VERSION ""

NS_ :

BS_:
BU_: MX5_ND2_2019
BO_ 576 Steering: 8 MX5_ND2_2019
   SG_ 0_SteeringTorque : 7|16@0+ (1,-32512) [0|1] "" MX5_ND2_2019

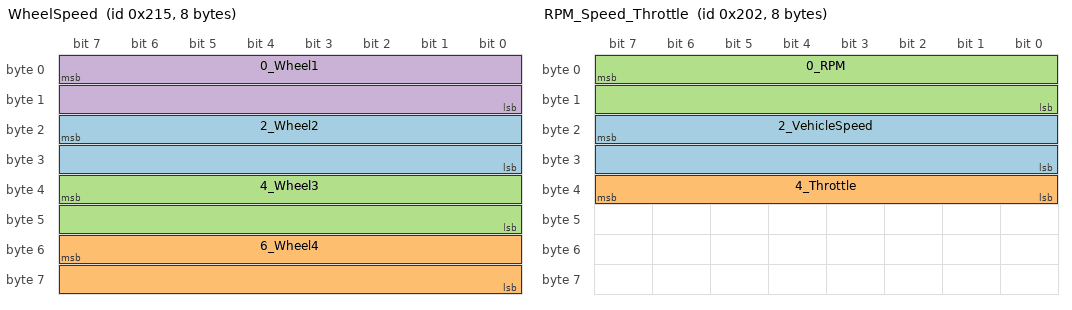
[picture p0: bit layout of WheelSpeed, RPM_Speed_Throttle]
BO_ 533 WheelSpeed: 8 MX5_ND2_2019
   SG_ 2_Wheel2 : 23|16@0+ (0.01,-100) [0|0] "" MX5_ND2_2019
   SG_ 6_Wheel4 : 55|16@0+ (0.01,-100) [0|0] "" MX5_ND2_2019
   SG_ 4_Wheel3 : 39|16@0+ (0.01,-100) [0|0] "" MX5_ND2_2019
   SG_ 0_Wheel1 : 7|16@0+ (0.01,-100) [0|0] "" MX5_ND2_2019

BO_ 357 Clutch_Gear_-_not_checked_yet: 8 MX5_ND2_2019
   SG_ 2_Clutch_Neutral : 23|8@0+ (1,0) [0|0] "" MX5_ND2_2019
   SG_ 6_CurrentGear : 55|8@0+ (1,0) [0|0] "" MX5_ND2_2019

BO_ 514 RPM_Speed_Throttle: 8 MX5_ND2_2019
   SG_ 2_VehicleSpeed : 23|16@0+ (0.01,0) [0|0] "kmh" Vector__XXX
   SG_ 4_Throttle : 39|8@0+ (0.4,0) [0|1] "percent" MX5_ND2_2019
   SG_ 0_RPM : 7|16@0+ (0.25,0) [0|0] "rpm" MX5_ND2_2019

BO_ 120 Brake: 8 MX5_ND2_2019
   SG_ BrakePressure : 39|16@0- (0.00152588,40) [0|100] "%" Vector__XXX

BO_ 2147484704 Temps: 8 MX5_ND2_2019
   SG_ 0_CoolantTemp : 7|8@0+ (1,-40) [0|1] "C" Vector__XXX

BO_ 2147484922 IAT: 8 MX5_ND2_2019
   SG_ 4_IntakeAirTemp : 39|8@0+ (1,-40) [0|1] "C" Vector__XXX

BO_ 2147483782 SteeringAngle: 8 MX5_ND2_2019
   SG_ 0_SteeringAngle : 7|16@0+ (-0.0228,365) [0|1] "" Vector__XXX

CM_ SG_ 357 6_CurrentGear "what_is_6th?";
BA_DEF_ BO_ "GenMsgBackgroundColor" STRING ;
BA_DEF_ BO_ "GenMsgForegroundColor" STRING ;
BA_DEF_DEF_ "GenMsgBackgroundColor" "#ffffff";
BA_DEF_DEF_ "GenMsgForegroundColor" "#000000";
VAL_ 357 2_Clutch_Neutral 22 "Neutral" 25 "Clutch-In" 22 "Clutch-Out";
VAL_ 357 6_CurrentGear 19 "Neutral_1st" 11 "2nd" 7 "3rd" 6 "4th" 5 "5th";
